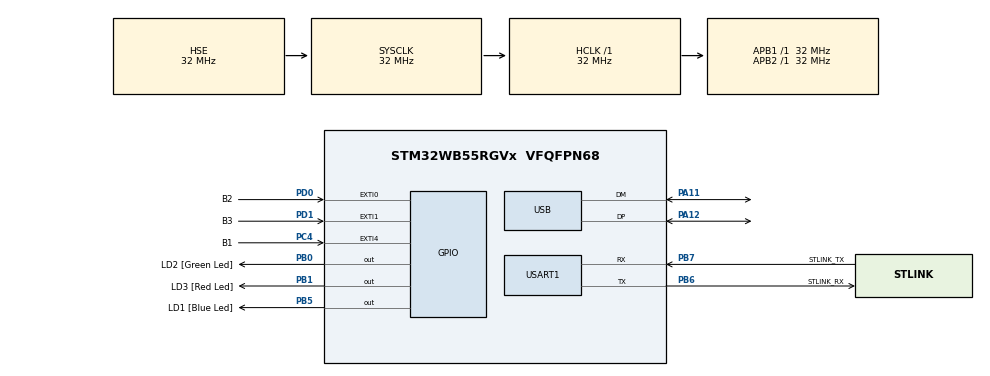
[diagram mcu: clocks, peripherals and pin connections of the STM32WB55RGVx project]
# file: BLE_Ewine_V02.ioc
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Dma.Request0=USART1_TX
Dma.USART1_TX.0.Direction=DMA_MEMORY_TO_PERIPH
Dma.USART1_TX.0.EventEnable=DISABLE
Dma.USART1_TX.0.Instance=DMA2_Channel4
Dma.USART1_TX.0.MemDataAlignment=DMA_MDATAALIGN_BYTE
Dma.USART1_TX.0.MemInc=DMA_MINC_ENABLE
Dma.USART1_TX.0.Mode=DMA_NORMAL
Dma.USART1_TX.0.PeriphDataAlignment=DMA_PDATAALIGN_BYTE
Dma.USART1_TX.0.PeriphInc=DMA_PINC_DISABLE
Dma.USART1_TX.0.Polarity=HAL_DMAMUX_REQ_GEN_RISING
Dma.USART1_TX.0.Priority=DMA_PRIORITY_LOW
Dma.USART1_TX.0.RequestNumber=1
Dma.USART1_TX.0.SignalID=NONE
Dma.USART1_TX.0.SyncEnable=DISABLE
Dma.USART1_TX.0.SyncPolarity=HAL_DMAMUX_SYNC_NO_EVENT
Dma.USART1_TX.0.SyncRequestNumber=1
Dma.USART1_TX.0.SyncSignalID=NONE
Mcu.Family=STM32WB
Mcu.Name=STM32WB55RGVx
Mcu.Package=VFQFPN68
NVIC.DMA2_Channel4_IRQn=true\:0\:0\:false\:false\:true\:false\:true\:true
NVIC.EXTI0_IRQn=true\:0\:0\:false\:false\:true\:true\:true\:true
NVIC.EXTI1_IRQn=true\:0\:0\:false\:false\:true\:true\:true\:true
NVIC.EXTI4_IRQn=true\:0\:0\:false\:false\:true\:true\:true\:true
NVIC.HSEM_IRQn=true\:0\:0\:false\:false\:true\:false\:true\:true
NVIC.IPCC_C1_RX_IRQn=true\:0\:0\:false\:false\:true\:true\:true\:true
NVIC.IPCC_C1_TX_IRQn=true\:0\:0\:false\:false\:true\:true\:true\:true
NVIC.PriorityGroup=NVIC_PRIORITYGROUP_4
NVIC.RTC_WKUP_IRQn=true\:0\:0\:false\:false\:true\:true\:true\:true
OSC_IN.Mode=HSE-External-Oscillator
OSC_IN.Signal=RCC_OSC_IN
OSC_OUT.Mode=HSE-External-Oscillator
OSC_OUT.Signal=RCC_OSC_OUT
PA11.Mode=Device
PA11.Signal=USB_DM
PA12.Mode=Device
PA12.Signal=USB_DP
PA13.GPIO_Label=JTMS
PA13.Mode=Serial_Wire
PA13.Signal=SYS_JTMS-SWDIO
PA14.GPIO_Label=JTCK
PA14.Mode=Serial_Wire
PA14.Signal=SYS_JTCK-SWCLK
PB0.GPIO_Label=LD2 [Green Led]
PB0.Signal=GPIO_Output
PB1.GPIO_Label=LD3 [Red Led]
PB1.Signal=GPIO_Output
PB5.GPIO_Label=LD1 [Blue Led]
PB5.Signal=GPIO_Output
PB6.GPIO_Label=STLINK_RX
PB6.GPIO_PuPd=GPIO_PULLUP
PB6.Mode=Asynchronous
PB6.Signal=USART1_TX
PB7.GPIO_Label=STLINK_TX
PB7.GPIO_PuPd=GPIO_PULLUP
PB7.Mode=Asynchronous
PB7.Signal=USART1_RX
PC13.Mode=SYS_WakeUp1
PC13.Signal=SYS_WKUP2
PC14-OSC32_IN.Mode=LSE-External-Oscillator
PC14-OSC32_IN.Signal=RCC_OSC32_IN
PC15-OSC32_OUT.Mode=LSE-External-Oscillator
PC15-OSC32_OUT.Signal=RCC_OSC32_OUT
PC4.GPIO_Label=B1
PC4.GPIO_PuPd=GPIO_PULLUP
PC4.Signal=GPXTI4
PD0.GPIO_Label=B2
PD0.GPIO_PuPd=GPIO_PULLUP
PD0.Signal=GPXTI0
PD1.GPIO_Label=B3
PD1.GPIO_PuPd=GPIO_PULLUP
PD1.Signal=GPXTI1
ProjectManager.HeapSize=0x200
ProjectManager.StackSize=0x400
ProjectManager.TargetToolchain=STM32CubeIDE
RCC.ADCFreq_Value=48000000
RCC.AHBFreq_Value=32000000
RCC.APB1Freq_Value=32000000
RCC.APB1TimFreq_Value=32000000
RCC.APB2Freq_Value=32000000
RCC.APB2TimFreq_Value=32000000
RCC.APB3Freq_Value=16000000
RCC.CortexFreq_Value=32000000
RCC.HCLKFreq_Value=32000000
RCC.HSE_VALUE=32000000
RCC.HSI48_VALUE=48000000
RCC.HSI_VALUE=16000000
RCC.PLLN=32
RCC.PLLSAI1N=24
RCC.SMPSCLockSelectionVirtual=RCC_SMPSCLKSOURCE_HSI
RCC.SMPSCLockSelectionVirtualVirtual=RCC_SMPSCLKSOURCE_HSI
RCC.SMPSDivider=1
RCC.SYSCLKFreq_VALUE=32000000
RCC.SYSCLKSource=RCC_SYSCLKSOURCE_HSE
RCC.USBFreq_Value=48000000
RCC.VCOOutputFreq_Value=128000000
RF1.Mode=RF1_Activate
RF1.Signal=RF_RF1
STM32_WPAN.AD_SERVICE_CLASS_UUID_1=FE ED
STM32_WPAN.AD_SERVICE_CLASS_UUID_1_INV=[ED, FE]
STM32_WPAN.AD_SERVICE_CLASS_UUID_2=BE EF
STM32_WPAN.AD_SERVICE_CLASS_UUID_2_INV=[EF, BE]
STM32_WPAN.AD_SERVICE_CLASS_UUID_NBR=2
STM32_WPAN.AD_TYPE_COMPLETE_LOCAL_NAME=Ewine
STM32_WPAN.AD_TYPE_COMPLETE_LOCAL_NAME_LENGTH=6
STM32_WPAN.CFG_DEBUG_APP_TRACE=1
STM32_WPAN.CFG_DEBUG_BLE_TRACE=1
STM32_WPAN.CFG_DEBUG_TRACE_FULL=1
STM32_WPAN.CFG_DEBUG_TRACE_UART=hw_uart1
STM32_WPAN.CFG_GAP_DEVICE_NAME=TPBLE
STM32_WPAN.CFG_GAP_DEVICE_NAME_LENGTH=5
STM32_WPAN.CFG_HW_USART1_ENABLED=1
STM32_WPAN.CUSTOM_P2P_SERVER=Disabled
STM32_WPAN.CUSTOM_TEMPLATE=Enabled
STM32_WPAN.GAP_PERIPHERAL_ROLE=1
STM32_WPAN.INCLUDE_AD_TYPE_16_BIT_SERV_UUID_CMPLT_LIST=1
STM32_WPAN.INCLUDE_AD_TYPE_COMPLETE_LOCAL_NAME=1
STM32_WPAN.INCLUDE_AD_TYPE_MANUFACTURER_SPECIFIC_DATA=1
STM32_WPAN.INCLUDE_AD_TYPE_TX_POWER_LEVEL=1
STM32_WPAN.NUMBER_OF_SERVICES=1
STM32_WPAN.SERVICE1_CHAR1_GATT_NOTIFY_READ_REQ_AND_WAIT_FOR_APPL_RESP=\ 
STM32_WPAN.SERVICE1_CHAR1_GATT_NOTIFY_WRITE_REQ_AND_WAIT_FOR_APPL_RESP=\ 
STM32_WPAN.SERVICE1_CHAR1_LENGTH_CHARACTERISTIC=CHAR_VALUE_LEN_VARIABLE
STM32_WPAN.SERVICE1_CHAR1_LONG_NAME=get_ssid
STM32_WPAN.SERVICE1_CHAR1_PROP_READ=CHAR_PROP_READ
STM32_WPAN.SERVICE1_CHAR1_PROP_WRITE_WITHOUT_RESP=CHAR_PROP_WRITE_WITHOUT_RESP
STM32_WPAN.SERVICE1_CHAR1_SHORT_NAME=gssid
STM32_WPAN.SERVICE1_CHAR1_UUID=AB CD
STM32_WPAN.SERVICE1_CHAR1_VALUE_LENGTH=30
STM32_WPAN.SERVICE1_CHAR2_GATT_NOTIFY_READ_REQ_AND_WAIT_FOR_APPL_RESP=\ 
STM32_WPAN.SERVICE1_CHAR2_GATT_NOTIFY_WRITE_REQ_AND_WAIT_FOR_APPL_RESP=\ 
STM32_WPAN.SERVICE1_CHAR2_LENGTH_CHARACTERISTIC=CHAR_VALUE_LEN_VARIABLE
STM32_WPAN.SERVICE1_CHAR2_LONG_NAME=get_password
STM32_WPAN.SERVICE1_CHAR2_PROP_READ=CHAR_PROP_READ
STM32_WPAN.SERVICE1_CHAR2_PROP_WRITE_WITHOUT_RESP=CHAR_PROP_WRITE_WITHOUT_RESP
STM32_WPAN.SERVICE1_CHAR2_SHORT_NAME=gpass
STM32_WPAN.SERVICE1_CHAR2_UUID=12 34
STM32_WPAN.SERVICE1_CHAR2_VALUE_LENGTH=30
STM32_WPAN.SERVICE1_LONG_NAME=First_service
STM32_WPAN.SERVICE1_NUMBER_OF_CHARACTERISTICS=2
STM32_WPAN.SERVICE1_SHORT_NAME=fs
STM32_WPAN.SERVICE1_UUID=FE ED
STM32_WPAN.SERVICE2_CHAR1_GATT_NOTIFY_READ_REQ_AND_WAIT_FOR_APPL_RESP=\ 
STM32_WPAN.SERVICE2_CHAR1_GATT_NOTIFY_WRITE_REQ_AND_WAIT_FOR_APPL_RESP=\ 
STM32_WPAN.SERVICE2_CHAR1_LONG_NAME=echo_char
STM32_WPAN.SERVICE2_CHAR1_PROP_NOTIFY=CHAR_PROP_NOTIFY
STM32_WPAN.SERVICE2_CHAR1_SHORT_NAME=ec
STM32_WPAN.SERVICE2_CHAR1_UUID=CD EF
STM32_WPAN.SERVICE2_LONG_NAME=echo_service
STM32_WPAN.SERVICE2_SHORT_NAME=es
STM32_WPAN.SERVICE2_UUID=BE EF
USART1.VirtualMode-Asynchronous=VM_ASYNC
USART1.WordLength=WORDLENGTH_8B
VP_HSEM_VS_HSEM.Mode=HSEM_Activate
VP_IPCC_VS_IPCC.Mode=IPCC_Activate
VP_RTC_VS_RTC_Activate.Mode=RTC_Enabled
VP_RTC_VS_RTC_WakeUp_intern.Mode=WakeUp
VP_SEQUENCER_VS_SEQUENCER.Mode=SEQUENCER_Enabled
VP_STM32_WPAN_VS_BLE_HOST.Mode=STM32_WPAN_Enabled
VP_TINY_LPM_VS_TINY_LPM.Mode=TINY_LPM_Enabled
board=NUCLEO-WB55RG

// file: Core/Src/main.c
/* USER CODE BEGIN Header */
/**
  ******************************************************************************
  * @file           : main.c
  * @brief          : Main program body
  ******************************************************************************
  * @attention
  *
  * Copyright (c) 2023 STMicroelectronics.
  * All rights reserved.
  *
  * This software is licensed under terms that can be found in the LICENSE file
  * in the root directory of this software component.
  * If no LICENSE file comes with this software, it is provided AS-IS.
  *
  ******************************************************************************
  */
/* USER CODE END Header */
#include "main.h"

IPCC_HandleTypeDef hipcc;

RTC_HandleTypeDef hrtc;

UART_HandleTypeDef huart1;
DMA_HandleTypeDef hdma_usart1_tx;

void SystemClock_Config(void);
void PeriphCommonClock_Config(void);
static void MX_GPIO_Init(void);
static void MX_DMA_Init(void);
static void MX_RF_Init(void);
static void MX_RTC_Init(void);
static void MX_IPCC_Init(void);
static void MX_USART1_UART_Init(void);
/* USER CODE BEGIN PFP */
int _write(int file, char *ptr, int len);
/* USER CODE END PFP */

/* USER CODE BEGIN 0 */
int _write(int file, char *ptr, int len)
{
	int DataIdx;
	for (DataIdx = 0; DataIdx < len; DataIdx++)
	{
		//__io_putchar(*ptr++);
		ITM_SendChar(*ptr++);
	}
	return len;
}
/* USER CODE END 0 */

int main(void)
{

  /* MCU Configuration--------------------------------------------------------*/

  /* Reset of all peripherals, Initializes the Flash interface and the Systick. */  HAL_Init();
  /* Config code for STM32_WPAN (HSE Tuning must be done before system clock configuration) */
  MX_APPE_Config();

  /* Configure the system clock */
  SystemClock_Config();

/* Configure the peripherals common clocks */
  PeriphCommonClock_Config();

  /* IPCC initialisation */
  MX_IPCC_Init();

  /* Initialize all configured peripherals */
  MX_GPIO_Init();
  MX_DMA_Init();
  MX_RF_Init();
  MX_RTC_Init();
  MX_USART1_UART_Init();

  /* Init code for STM32_WPAN */
  MX_APPE_Init();

  /* Infinite loop */
  while (1)
  {
    MX_APPE_Process();

  }
}

void SystemClock_Config(void)
{
  RCC_OscInitTypeDef RCC_OscInitStruct = {0};
  RCC_ClkInitTypeDef RCC_ClkInitStruct = {0};

  /** Configure the main internal regulator output voltage
  */
  __HAL_PWR_VOLTAGESCALING_CONFIG(PWR_REGULATOR_VOLTAGE_SCALE1);

  /** Initializes the RCC Oscillators according to the specified parameters
  * in the RCC_OscInitTypeDef structure.
  */
  RCC_OscInitStruct.OscillatorType = RCC_OSCILLATORTYPE_HSI|RCC_OSCILLATORTYPE_LSI1
                              |RCC_OSCILLATORTYPE_HSE;
  RCC_OscInitStruct.HSEState = RCC_HSE_ON;
  RCC_OscInitStruct.HSIState = RCC_HSI_ON;
  RCC_OscInitStruct.HSICalibrationValue = RCC_HSICALIBRATION_DEFAULT;
  RCC_OscInitStruct.LSIState = RCC_LSI_ON;
  RCC_OscInitStruct.PLL.PLLState = RCC_PLL_NONE;
  if (HAL_RCC_OscConfig(&RCC_OscInitStruct) != HAL_OK)
  {
    Error_Handler();
  }

  /** Configure the SYSCLKSource, HCLK, PCLK1 and PCLK2 clocks dividers
  */
  RCC_ClkInitStruct.ClockType = RCC_CLOCKTYPE_HCLK4|RCC_CLOCKTYPE_HCLK2
                              |RCC_CLOCKTYPE_HCLK|RCC_CLOCKTYPE_SYSCLK
                              |RCC_CLOCKTYPE_PCLK1|RCC_CLOCKTYPE_PCLK2;
  RCC_ClkInitStruct.SYSCLKSource = RCC_SYSCLKSOURCE_HSE;
  RCC_ClkInitStruct.AHBCLKDivider = RCC_SYSCLK_DIV1;
  RCC_ClkInitStruct.APB1CLKDivider = RCC_HCLK_DIV1;
  RCC_ClkInitStruct.APB2CLKDivider = RCC_HCLK_DIV1;
  RCC_ClkInitStruct.AHBCLK2Divider = RCC_SYSCLK_DIV1;
  RCC_ClkInitStruct.AHBCLK4Divider = RCC_SYSCLK_DIV1;

  if (HAL_RCC_ClockConfig(&RCC_ClkInitStruct, FLASH_LATENCY_1) != HAL_OK)
  {
    Error_Handler();
  }
}

void PeriphCommonClock_Config(void)
{
  RCC_PeriphCLKInitTypeDef PeriphClkInitStruct = {0};

  /** Initializes the peripherals clock
  */
  PeriphClkInitStruct.PeriphClockSelection = RCC_PERIPHCLK_SMPS|RCC_PERIPHCLK_RFWAKEUP;
  PeriphClkInitStruct.RFWakeUpClockSelection = RCC_RFWKPCLKSOURCE_HSE_DIV1024;
  PeriphClkInitStruct.SmpsClockSelection = RCC_SMPSCLKSOURCE_HSI;
  PeriphClkInitStruct.SmpsDivSelection = RCC_SMPSCLKDIV_RANGE0;

  if (HAL_RCCEx_PeriphCLKConfig(&PeriphClkInitStruct) != HAL_OK)
  {
    Error_Handler();
  }
}

static void MX_IPCC_Init(void)
{

  hipcc.Instance = IPCC;
  if (HAL_IPCC_Init(&hipcc) != HAL_OK)
  {
    Error_Handler();
  }

}

static void MX_RF_Init(void)
{

}

static void MX_RTC_Init(void)
{

  /** Initialize RTC Only
  */
  hrtc.Instance = RTC;
  hrtc.Init.HourFormat = RTC_HOURFORMAT_24;
  hrtc.Init.AsynchPrediv = CFG_RTC_ASYNCH_PRESCALER;
  hrtc.Init.SynchPrediv = CFG_RTC_SYNCH_PRESCALER;
  hrtc.Init.OutPut = RTC_OUTPUT_DISABLE;
  hrtc.Init.OutPutPolarity = RTC_OUTPUT_POLARITY_HIGH;
  hrtc.Init.OutPutType = RTC_OUTPUT_TYPE_OPENDRAIN;
  hrtc.Init.OutPutRemap = RTC_OUTPUT_REMAP_NONE;
  if (HAL_RTC_Init(&hrtc) != HAL_OK)
  {
    Error_Handler();
  }

  /** Enable the WakeUp
  */
  if (HAL_RTCEx_SetWakeUpTimer_IT(&hrtc, 0, RTC_WAKEUPCLOCK_RTCCLK_DIV16) != HAL_OK)
  {
    Error_Handler();
  }

}

static void MX_USART1_UART_Init(void)
{

  huart1.Instance = USART1;
  huart1.Init.BaudRate = 115200;
  huart1.Init.WordLength = UART_WORDLENGTH_8B;
  huart1.Init.StopBits = UART_STOPBITS_1;
  huart1.Init.Parity = UART_PARITY_NONE;
  huart1.Init.Mode = UART_MODE_TX_RX;
  huart1.Init.HwFlowCtl = UART_HWCONTROL_NONE;
  huart1.Init.OverSampling = UART_OVERSAMPLING_8;
  huart1.Init.OneBitSampling = UART_ONE_BIT_SAMPLE_DISABLE;
  huart1.Init.ClockPrescaler = UART_PRESCALER_DIV1;
  huart1.AdvancedInit.AdvFeatureInit = UART_ADVFEATURE_NO_INIT;
  if (HAL_UART_Init(&huart1) != HAL_OK)
  {
    Error_Handler();
  }
  if (HAL_UARTEx_SetTxFifoThreshold(&huart1, UART_TXFIFO_THRESHOLD_1_8) != HAL_OK)
  {
    Error_Handler();
  }
  if (HAL_UARTEx_SetRxFifoThreshold(&huart1, UART_RXFIFO_THRESHOLD_1_8) != HAL_OK)
  {
    Error_Handler();
  }
  if (HAL_UARTEx_DisableFifoMode(&huart1) != HAL_OK)
  {
    Error_Handler();
  }

}

static void MX_DMA_Init(void)
{

  /* DMA controller clock enable */
  __HAL_RCC_DMAMUX1_CLK_ENABLE();
  __HAL_RCC_DMA2_CLK_ENABLE();

  /* DMA interrupt init */
  /* DMA2_Channel4_IRQn interrupt configuration */
  HAL_NVIC_SetPriority(DMA2_Channel4_IRQn, 0, 0);
  HAL_NVIC_EnableIRQ(DMA2_Channel4_IRQn);

}

static void MX_GPIO_Init(void)
{
  GPIO_InitTypeDef GPIO_InitStruct = {0};

  /* GPIO Ports Clock Enable */
  __HAL_RCC_GPIOC_CLK_ENABLE();
  __HAL_RCC_GPIOB_CLK_ENABLE();
  __HAL_RCC_GPIOA_CLK_ENABLE();
  __HAL_RCC_GPIOD_CLK_ENABLE();

  /*Configure GPIO pin Output Level */
  HAL_GPIO_WritePin(GPIOB, LD2_Pin|LD3_Pin|LD1_Pin, GPIO_PIN_RESET);

  /*Configure GPIO pin : B1_Pin */
  GPIO_InitStruct.Pin = B1_Pin;
  GPIO_InitStruct.Mode = GPIO_MODE_IT_RISING;
  GPIO_InitStruct.Pull = GPIO_PULLUP;
  HAL_GPIO_Init(B1_GPIO_Port, &GPIO_InitStruct);

  /*Configure GPIO pins : LD2_Pin LD3_Pin LD1_Pin */
  GPIO_InitStruct.Pin = LD2_Pin|LD3_Pin|LD1_Pin;
  GPIO_InitStruct.Mode = GPIO_MODE_OUTPUT_PP;
  GPIO_InitStruct.Pull = GPIO_NOPULL;
  GPIO_InitStruct.Speed = GPIO_SPEED_FREQ_LOW;
  HAL_GPIO_Init(GPIOB, &GPIO_InitStruct);

  /*Configure GPIO pins : B2_Pin B3_Pin */
  GPIO_InitStruct.Pin = B2_Pin|B3_Pin;
  GPIO_InitStruct.Mode = GPIO_MODE_IT_RISING;
  GPIO_InitStruct.Pull = GPIO_PULLUP;
  HAL_GPIO_Init(GPIOD, &GPIO_InitStruct);

  /* EXTI interrupt init*/
  HAL_NVIC_SetPriority(EXTI0_IRQn, 0, 0);
  HAL_NVIC_EnableIRQ(EXTI0_IRQn);

  HAL_NVIC_SetPriority(EXTI1_IRQn, 0, 0);
  HAL_NVIC_EnableIRQ(EXTI1_IRQn);

  HAL_NVIC_SetPriority(EXTI4_IRQn, 0, 0);
  HAL_NVIC_EnableIRQ(EXTI4_IRQn);

}

void Error_Handler(void)
{
  __disable_irq();
  while (1)
  {
  }
}
